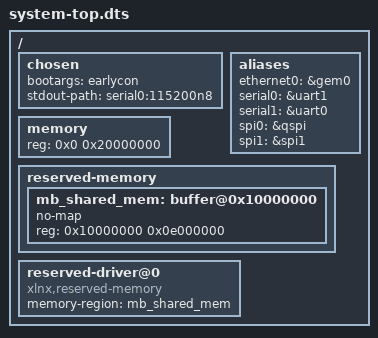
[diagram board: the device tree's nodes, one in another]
/*
 * CAUTION: This file is automatically generated by Xilinx.
 * Version:  
 * Today is: Mon Feb 18 20:24:47 2019
 */


/dts-v1/;
/include/ "zynq-7000.dtsi"
/include/ "pl.dtsi"
/include/ "pcw.dtsi"
/ {
	chosen {
		bootargs = "earlycon";
		stdout-path = "serial0:115200n8";
	};
	aliases {
		ethernet0 = &gem0;
		serial0 = &uart1;
		serial1 = &uart0;
//		serial1 = &axi_uartlite_0;
		spi0 = &qspi;
		spi1 = &spi1;
	};
	memory {
		device_type = "memory";
		reg = <0x0 0x20000000>;
	};


   reserved-memory {
      #address-cells = <1>;
      #size-cells = <1>;
      ranges;
  
      mb_shared_mem: buffer@0x10000000 {
         no-map;
         reg = <0x10000000 0x0e000000>;
      };
   };
  
   reserved-driver@0 {
      compatible = "xlnx,reserved-memory";
      memory-region = <&mb_shared_mem>;
   };



};
